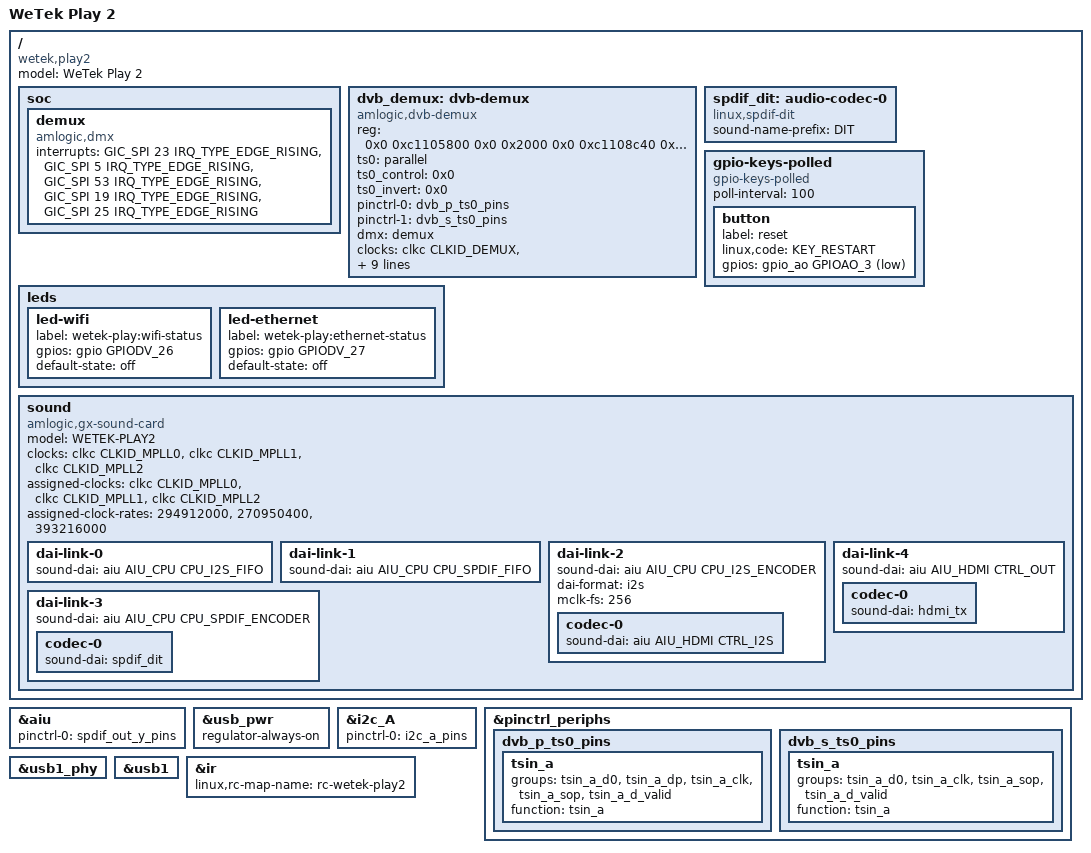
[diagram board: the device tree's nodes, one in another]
// SPDX-License-Identifier: (GPL-2.0+ OR MIT)
/*
 * Copyright (c) 2016 BayLibre, Inc.
 * Author: Neil Armstrong <narmstrong@baylibre.com>
 */

/dts-v1/;

#include "meson-gxbb-wetek.dtsi"
#include <dt-bindings/input/input.h>
#include <dt-bindings/sound/meson-aiu.h>

/ {
	compatible = "wetek,play2", "amlogic,meson-gxbb";
	model = "WeTek Play 2";

	soc {
		demux: demux {
			compatible = "amlogic,dmx";
			interrupts = <GIC_SPI 23 IRQ_TYPE_EDGE_RISING>,
				     <GIC_SPI 5  IRQ_TYPE_EDGE_RISING>,
				     <GIC_SPI 53 IRQ_TYPE_EDGE_RISING>,
				     <GIC_SPI 19 IRQ_TYPE_EDGE_RISING>,
				     <GIC_SPI 25 IRQ_TYPE_EDGE_RISING>;
			interrupt-names = "demux0_irq", "demux1_irq",
					  "demux2_irq", "dvr0_irq",
					  "dvr1_irq";
		};
	};

	dvb_demux: dvb-demux {
		compatible = "amlogic,dvb-demux";
		reg = <0x0 0xc1105800 0x0 0x2000 0x0 0xc1108c40 0x0 0x100>;

		status = "okay";
		ts0 = "parallel";
		ts0_control = <0x0>;
		ts0_invert = <0x0>;
		pinctrl-names = "p_ts0", "s_ts0";
		pinctrl-0 = <&dvb_p_ts0_pins>;
		pinctrl-1 = <&dvb_s_ts0_pins>;
		dmx = <&demux>;

		clocks = <&clkc CLKID_DEMUX
			  &clkc CLKID_ASYNC_FIFO
			  &clkc CLKID_AHB_ARB0
			  &clkc CLKID_HIU_IFACE>;
		clock-names = "demux", "asyncfifo",
			      "ahbarb0", "uparsertop";

		resets = <&reset RESET_DEMUX>,
			 <&reset RESET_DEMUX_DES>,
			 <&reset RESET_DEMUX_RESET_0>,
			 <&reset RESET_DEMUX_RESET_1>,
			 <&reset RESET_DEMUX_RESET_2>,
			 <&reset RESET_PERIPHS_ASYNC_0>,
			 <&reset RESET_PERIPHS_ASYNC_1>;
		reset-names = "demux_rst", "des_rst", "demux0_rst",
			      "demux1_rst", "demux2_rst",
			      "async0_rst", "async1_rst";
	};

	spdif_dit: audio-codec-0 {
		#sound-dai-cells = <0>;
		compatible = "linux,spdif-dit";
		sound-name-prefix = "DIT";
	};

	leds {
		led-wifi {
			label = "wetek-play:wifi-status";
			gpios = <&gpio GPIODV_26 GPIO_ACTIVE_HIGH>;
			default-state = "off";
		};

		led-ethernet {
			label = "wetek-play:ethernet-status";
			gpios = <&gpio GPIODV_27 GPIO_ACTIVE_HIGH>;
			default-state = "off";
		};
	};

	gpio-keys-polled {
		compatible = "gpio-keys-polled";
		poll-interval = <100>;

		button {
			label = "reset";
			linux,code = <KEY_RESTART>;
			gpios = <&gpio_ao GPIOAO_3 GPIO_ACTIVE_LOW>;
		};
	};

	sound {
		compatible = "amlogic,gx-sound-card";
		model = "WETEK-PLAY2";
		clocks = <&clkc CLKID_MPLL0>,
			 <&clkc CLKID_MPLL1>,
			 <&clkc CLKID_MPLL2>;

		assigned-clocks = <&clkc CLKID_MPLL0>,
				  <&clkc CLKID_MPLL1>,
				  <&clkc CLKID_MPLL2>;
		assigned-clock-rates = <294912000>,
				       <270950400>,
				       <393216000>;

		dai-link-0 {
			sound-dai = <&aiu AIU_CPU CPU_I2S_FIFO>;
		};

		dai-link-1 {
			sound-dai = <&aiu AIU_CPU CPU_SPDIF_FIFO>;
		};

		dai-link-2 {
			sound-dai = <&aiu AIU_CPU CPU_I2S_ENCODER>;
			dai-format = "i2s";
			mclk-fs = <256>;

			codec-0 {
				sound-dai = <&aiu AIU_HDMI CTRL_I2S>;
			};
		};

		dai-link-3 {
			sound-dai = <&aiu AIU_CPU CPU_SPDIF_ENCODER>;

			codec-0 {
				sound-dai = <&spdif_dit>;
			};
		};

		dai-link-4 {
			sound-dai = <&aiu AIU_HDMI CTRL_OUT>;

			codec-0 {
				sound-dai = <&hdmi_tx>;
			};
		};
	};
};

&aiu {
	status = "okay";
	pinctrl-0 = <&spdif_out_y_pins>;
	pinctrl-names = "default";
};

/*
 * GPIODV_24 is shared between i2c_A SCK and the usb_pwr regulator GPIO.
 * Override usb_pwr to remove the GPIO so i2c_A can function for the NIM.
 */
&usb_pwr {
	/delete-property/ gpio;
	/delete-property/ enable-active-high;
	regulator-always-on;
};

&i2c_A {
	status = "okay";
	pinctrl-0 = <&i2c_a_pins>;
	pinctrl-names = "default";
};

&pinctrl_periphs {
	dvb_p_ts0_pins: dvb_p_ts0_pins {
		tsin_a {
			groups = "tsin_a_d0",
				 "tsin_a_dp",
				 "tsin_a_clk",
				 "tsin_a_sop",
				 "tsin_a_d_valid";
			function = "tsin_a";
		};
	};

	dvb_s_ts0_pins: dvb_s_ts0_pins {
		tsin_a {
			groups = "tsin_a_d0",
				 "tsin_a_clk",
				 "tsin_a_sop",
				 "tsin_a_d_valid";
			function = "tsin_a";
		};
	};
};

&usb1_phy {
	status = "okay";
};

&usb1 {
	status = "okay";
};

&ir {
	linux,rc-map-name = "rc-wetek-play2";
};
